AUTOSAR XML (schema 4-1-3)
standard types defined: boolean, sint8, uint16, uint32, uint8, boolean_CompuMethod, boolean_DataConstr, sint8_DataConstr, uint16_DataConstr, uint32_DataConstr, uint8_DataConstr
package /MICROSAR/Dem_swc/DataTypes
  5 x impl type:
    Dem_DebounceResetStatusType: compu {0=DEM_DEBOUNCE_STATUS_FREEZE, 1=DEM_DEBOUNCE_STATUS_RESET}, range raw 0..255, implementation-data-type=ImplementationDataTypes/uint8
    Dem_DTCFormatType: compu {0=DEM_DTC_FORMAT_OBD, 1=DEM_DTC_FORMAT_UDS, 2=DEM_DTC_FORMAT_J1939}, range raw 0..2, implementation-data-type=ImplementationDataTypes/uint8
    Dem_EventStatusType:
      compu {0=DEM_EVENT_STATUS_PASSED, 1=DEM_EVENT_STATUS_FAILED, 2=DEM_EVENT_STATUS_PREPASSED, 3=DEM_EVENT_STATUS_PREFAILED, 4=DEM_EVENT_STATUS_FDC_THRESHOLD_REACHED, 5=DEM_EVENT_STATUS_PASSED_CONDITIONS_NOT_FULFILLED, 6=DEM_EVENT_STATUS_FAILED_CONDITIONS_NOT_FULFILLED, 7=DEM_EVENT_STATUS_PREPASSED_CONDITIONS_NOT_FULFILLED, 8=DEM_EVENT_STATUS_PREFAILED_CONDITIONS_NOT_FULFILLED}
      range raw 0..255
      implementation-data-type=ImplementationDataTypes/uint8
    Dem_MaxDataValueType: category=ARRAY, sw-calibration-access=READ-ONLY
      element Dem_MaxDataValueTypeElement: array-size=40, array-size-semantics=FIXED-SIZE, implementation-data-type=ImplementationDataTypes/uint8
    Dem_UdsStatusByteType:
      compu {mask 1: 1=DEM_UDS_STATUS_TF (bit 0: TestFailed), mask 2: 2=DEM_UDS_STATUS_TFTOC (bit 1: TestFailedThisOperationCycle), mask 4: 4=DEM_UDS_STATUS_PDTC (bit 2: PendingDTC), mask 8: 8=DEM_UDS_STATUS_CDTC (bit 3: ConfirmedDTC), mask 16: 16=DEM_UDS_STATUS_TNCSLC (bit 4: TestNotCompletedSinceLastClear), mask 32: 32=DEM_UDS_STATUS_TFSLC (bit 5: TestFailedSinceLastClear), mask 64: 64=DEM_UDS_STATUS_TNCTOC (bit 6: TestNotCompletedThisOperationCycle), mask 128: 128=DEM_UDS_STATUS_WIR (bit 7: WarningIndicatorRequested)}
      range raw 0..255
      implementation-data-type=ImplementationDataTypes/uint8
package /MICROSAR/Dem_swc/Interfaces
  client server interface DiagnosticMonitor: is-service=true, service-kind=DIAGNOSTIC-EVENT-MANAGER
    11 x operation:
      GetDTCOfEvent: possible-error=[DEM_E_NO_DTC_AVAILABLE, DiagnosticMonitor/E_NOT_OK]
        arg DTCFormat: type=Dem_DTCFormatType, direction=IN, server-argument-impl-policy=USE-ARGUMENT-TYPE
        arg DTCOfEvent: type=ImplementationDataTypes/uint32, direction=OUT, server-argument-impl-policy=USE-ARGUMENT-TYPE
      GetEventExtendedDataRecordEx: possible-error=[DEM_BUFFER_TOO_SMALL, DEM_NO_SUCH_ELEMENT, DiagnosticMonitor/E_NOT_OK]
        arg RecordNumber: type=ImplementationDataTypes/uint8, direction=IN, server-argument-impl-policy=USE-ARGUMENT-TYPE
        arg DestBuffer: type=Dem_MaxDataValueType, direction=OUT, server-argument-impl-policy=USE-ARGUMENT-TYPE
        arg BufSize: type=ImplementationDataTypes/uint16, direction=INOUT, server-argument-impl-policy=USE-ARGUMENT-TYPE
      GetEventFailed: possible-error=DiagnosticMonitor/E_NOT_OK
        arg EventFailed: type=ImplementationDataTypes/boolean, direction=OUT, server-argument-impl-policy=USE-ARGUMENT-TYPE
      GetEventFreezeFrameDataEx: possible-error=[DEM_BUFFER_TOO_SMALL, DEM_NO_SUCH_ELEMENT, DiagnosticMonitor/E_NOT_OK]
        4 x arg, all with server-argument-impl-policy=USE-ARGUMENT-TYPE:
          RecordNumber: type=ImplementationDataTypes/uint8, direction=IN
          DataId: type=ImplementationDataTypes/uint16, direction=IN
          DestBuffer: type=Dem_MaxDataValueType, direction=OUT
          BufSize: type=ImplementationDataTypes/uint16, direction=INOUT
      GetEventStatus: possible-error=DiagnosticMonitor/E_NOT_OK
        arg UDSStatusByte: type=Dem_UdsStatusByteType, direction=OUT, server-argument-impl-policy=USE-ARGUMENT-TYPE
      GetEventTested: possible-error=DiagnosticMonitor/E_NOT_OK
        arg EventTested: type=ImplementationDataTypes/boolean, direction=OUT, server-argument-impl-policy=USE-ARGUMENT-TYPE
      GetEventUdsStatus: possible-error=DiagnosticMonitor/E_NOT_OK
        arg UDSStatusByte: type=Dem_UdsStatusByteType, direction=OUT, server-argument-impl-policy=USE-ARGUMENT-TYPE
      GetFaultDetectionCounter: possible-error=[DEM_E_NO_FDC_AVAILABLE, DiagnosticMonitor/E_NOT_OK]
        arg FaultDetectionCounter: type=sint8, direction=OUT, server-argument-impl-policy=USE-ARGUMENT-TYPE
      ResetEventDebounceStatus: possible-error=DiagnosticMonitor/E_NOT_OK
        arg DebounceResetStatus: type=Dem_DebounceResetStatusType, direction=IN, server-argument-impl-policy=USE-ARGUMENT-TYPE
      ResetEventStatus: possible-error=DiagnosticMonitor/E_NOT_OK
      SetEventStatus: possible-error=DiagnosticMonitor/E_NOT_OK
        arg EventStatus: type=Dem_EventStatusType, direction=IN, server-argument-impl-policy=USE-ARGUMENT-TYPE
    5 x error:
      DEM_BUFFER_TOO_SMALL: error-code=21
      DEM_E_NO_DTC_AVAILABLE: error-code=10
      DEM_E_NO_FDC_AVAILABLE: error-code=14
      DEM_NO_SUCH_ELEMENT: error-code=48
      E_NOT_OK: error-code=1
package /UAES/ASW/CompuMethods
  compu method CM_boolean: 0=FALSE, 1=TRUE
package /UAES/ASW/DataConstrs
  range DC_boolean: raw 0..1
  range DC_uint16: phys 0..6553.5, raw 0..65535
  range DC_uint32: raw 0..4294967295
  range DC_uint8: raw 0..255
package /UAES/ASW/DataTypeMappingSets
  data type mapping set DTMS_ChrgPlgPosn_VD
package /UAES/ASW/PortInterfaces
  client server interface IoHwAb_IoSigDio
    operation Di_Get: possible-error=IoHwAb_IoSigDio/E_NOT_OK
      arg id_u16: type=ImplementationDataTypes/uint16, direction=IN, server-argument-impl-policy=USE-ARGUMENT-TYPE
      arg val_u8: type=ImplementationDataTypes/uint8, direction=OUT, server-argument-impl-policy=USE-ARGUMENT-TYPE
    operation Do_Set: possible-error=IoHwAb_IoSigDio/E_NOT_OK
      arg id_u16: type=ImplementationDataTypes/uint16, direction=IN, server-argument-impl-policy=USE-ARGUMENT-TYPE
      arg val_u8: type=ImplementationDataTypes/uint8, direction=IN, server-argument-impl-policy=USE-ARGUMENT-TYPE
    error E_NOT_OK: error-code=1
  client server interface IoHwAb_IoSigIcu
    operation Icu_GetPerdAndDuty: possible-error=IoHwAb_IoSigIcu/E_NOT_OK
      arg id_u16: type=ImplementationDataTypes/uint16, direction=IN, server-argument-impl-policy=USE-ARGUMENT-TYPE
      arg duty_u32: type=ImplementationDataTypes/uint32, direction=OUT, server-argument-impl-policy=USE-ARGUMENT-TYPE
      arg period_u32: type=ImplementationDataTypes/uint32, direction=OUT, server-argument-impl-policy=USE-ARGUMENT-TYPE
    error E_NOT_OK: error-code=1
  5 x sender receiver interface:
    BattU_bVoltEnbPinDiag: invalidation-policy{data-element=BattU_bVoltEnbPinDiag/Val, handle-invalid=DONT-INVALIDATE}
      data Val: sw-calibration-access=READ-ONLY, type=ImplementationDataTypes/boolean
    ChrgPlgPosn_st: invalidation-policy{data-element=ChrgPlgPosn_st/Val, handle-invalid=DONT-INVALIDATE}
      data Val: sw-calibration-access=READ-ONLY, type=ImplementationDataTypes/uint8
    ChrgPlgPosn_stRaw: invalidation-policy{data-element=ChrgPlgPosn_stRaw/Val, handle-invalid=DONT-INVALIDATE}
      data Val: sw-calibration-access=READ-ONLY, type=ImplementationDataTypes/uint8
    ChrgPlgPosn_stRaw2: invalidation-policy{data-element=ChrgPlgPosn_stRaw2/Val, handle-invalid=DONT-INVALIDATE}
      data Val: sw-calibration-access=READ-ONLY, type=ImplementationDataTypes/uint8
    VehCoorn_stPwrMod: invalidation-policy{data-element=VehCoorn_stPwrMod/Val, handle-invalid=DONT-INVALIDATE}
      data Val: sw-calibration-access=READ-ONLY, type=ImplementationDataTypes/uint8
package /UAES/ASW/SwComponentTypes
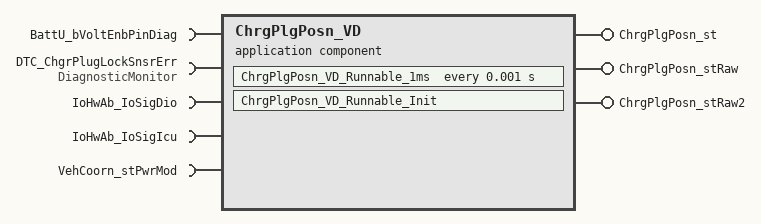
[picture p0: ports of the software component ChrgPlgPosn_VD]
  application sw component type ChrgPlgPosn_VD
    provide port ChrgPlgPosn_st: nonqueued-sender-com-spec{data-element=ChrgPlgPosn_st/Val, init-value=0}, provided-interface=ChrgPlgPosn_st
    provide port ChrgPlgPosn_stRaw: nonqueued-sender-com-spec{data-element=ChrgPlgPosn_stRaw/Val, init-value=0}, provided-interface=ChrgPlgPosn_stRaw
    provide port ChrgPlgPosn_stRaw2: nonqueued-sender-com-spec{data-element=ChrgPlgPosn_stRaw2/Val, init-value=0}, provided-interface=ChrgPlgPosn_stRaw2
    5 x require port:
      BattU_bVoltEnbPinDiag: nonqueued-receiver-com-spec{data-element=BattU_bVoltEnbPinDiag/Val, filter=data-filter-type=ALWAYS, init-value=0}, required-interface=BattU_bVoltEnbPinDiag
      DTC_ChgrPlugLockSnsrErr: required-interface=DiagnosticMonitor
        required-com-specs:
          GetDTCOfEvent
          GetEventExtendedDataRecordEx
          GetEventFailed
          GetEventFreezeFrameDataEx
          GetEventStatus
          GetEventTested
          GetEventUdsStatus
          GetFaultDetectionCounter
          ResetEventDebounceStatus
          ResetEventStatus
          SetEventStatus
      IoHwAb_IoSigDio: required-com-specs=[Di_Get, Do_Set], required-interface=IoHwAb_IoSigDio
      IoHwAb_IoSigIcu: client-com-spec=Icu_GetPerdAndDuty, required-interface=IoHwAb_IoSigIcu
      VehCoorn_stPwrMod: nonqueued-receiver-com-spec{data-element=VehCoorn_stPwrMod/Val, filter=data-filter-type=ALWAYS, init-value=0}, required-interface=VehCoorn_stPwrMod
    behavior ChrgPlgPosn_VD_InternalBehavior: data-type-mapping=DTMS_ChrgPlgPosn_VD
      timing event TMT_ChrgPlgPosn_VD_Runnable_1ms: start-on-event=ChrgPlgPosn_VD_Runnable_1ms, period=0.001
      init event ChrgPlgPosn_VD_InitEvent: start-on-event=ChrgPlgPosn_VD_Runnable_Init
      runnable ChrgPlgPosn_VD_Runnable_1ms
        data-read-access:
          access READ_BattU_bVoltEnbPinDiag_Val: accessed-variable=BattU_bVoltEnbPinDiag.Val
          access READ_VehCoorn_stPwrMod_Val: accessed-variable=VehCoorn_stPwrMod.Val
        data-write-access:
          access WRITE_ChrgPlgPosn_st_Val: accessed-variable=ChrgPlgPosn_st.Val
          access WRITE_ChrgPlgPosn_stRaw_Val: accessed-variable=ChrgPlgPosn_stRaw.Val
          access WRITE_ChrgPlgPosn_stRaw2_Val: accessed-variable=ChrgPlgPosn_stRaw2.Val
        6 x sync call:
          SC_DTC_ChgrPlugLockSnsrErr_GetEventFailed: operation=DTC_ChgrPlugLockSnsrErr.GetEventFailed, timeout=1E-06
          SC_DTC_ChgrPlugLockSnsrErr_GetEventTested: operation=DTC_ChgrPlugLockSnsrErr.GetEventTested, timeout=1E-06
          SC_DTC_ChgrPlugLockSnsrErr_ResetEventDebounceStatus: operation=DTC_ChgrPlugLockSnsrErr.ResetEventDebounceStatus, timeout=1E-06
          SC_DTC_ChgrPlugLockSnsrErr_SetEventStatus: operation=DTC_ChgrPlugLockSnsrErr.SetEventStatus, timeout=1E-06
          SC_IoHwAb_IoSigDio_Di_Get: operation=IoHwAb_IoSigDio.Di_Get, timeout=0
          SC_IoHwAb_IoSigIcu_Icu_GetPerdAndDuty: operation=IoHwAb_IoSigIcu.Icu_GetPerdAndDuty, timeout=0
      runnable ChrgPlgPosn_VD_Runnable_Init
  swc implementation Implementation_ChrgPlgPosn_VD: behavior=ChrgPlgPosn_VD_InternalBehavior
    code-descriptors:
      code Default: artifact-descriptors=autosar-engineering-object={short-label=Default, category=SWSRC}
package /UAES/ASW/Units
  unit NoUnit: factor-si-to-unit=1, offset-si-to-unit=0
